VERSION ""

NS_ :

BS_:

BU_:

BO_ 3221225472 VECTOR__INDEPENDENT_SIG_MSG: 0 Vector__XXX
 SG_ NewSignal_0005 : 0|8@1+ (1,0) [0|0] "" Vector__XXX
 SG_ NewSignal_0006 : 8|8@1+ (1,0) [0|0] "" Vector__XXX
 SG_ STATE : 0|8@1+ (1,0) [0|0] "" Vector__XXX
 SG_ NODE_ID : 8|8@1+ (1,0) [1|127] "" Vector__XXX

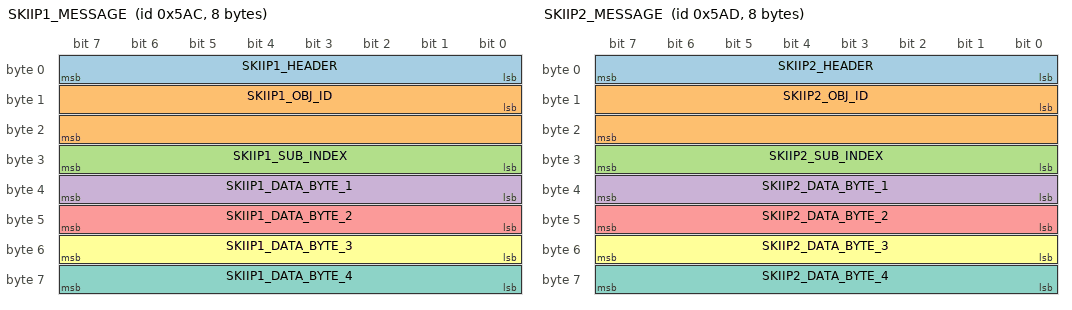
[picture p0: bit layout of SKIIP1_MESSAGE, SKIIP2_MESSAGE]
BO_ 1452 SKIIP1_MESSAGE: 8 Vector__XXX
 SG_ SKIIP1_HEADER : 0|8@1+ (1,0) [0|255] "" Vector__XXX
 SG_ SKIIP1_OBJ_ID : 8|16@1+ (1,0) [0|65535] "" Vector__XXX
 SG_ SKIIP1_SUB_INDEX : 24|8@1+ (1,0) [0|255] "" Vector__XXX
 SG_ SKIIP1_DATA_BYTE_1 : 32|8@1+ (1,0) [0|255] "" Vector__XXX
 SG_ SKIIP1_DATA_BYTE_2 : 40|8@1+ (1,0) [0|255] "" Vector__XXX
 SG_ SKIIP1_DATA_BYTE_3 : 48|8@1+ (1,0) [0|255] "" Vector__XXX
 SG_ SKIIP1_DATA_BYTE_4 : 56|8@1+ (1,0) [0|255] "" Vector__XXX

BO_ 1453 SKIIP2_MESSAGE: 8 Vector__XXX
 SG_ SKIIP2_HEADER : 0|8@1+ (1,0) [0|255] "" Vector__XXX
 SG_ SKIIP2_OBJ_ID : 8|16@1+ (1,0) [0|65535] "" Vector__XXX
 SG_ SKIIP2_SUB_INDEX : 24|8@1+ (1,0) [0|255] "" Vector__XXX
 SG_ SKIIP2_DATA_BYTE_1 : 32|8@1+ (1,0) [0|255] "" Vector__XXX
 SG_ SKIIP2_DATA_BYTE_2 : 40|8@1+ (1,0) [0|255] "" Vector__XXX
 SG_ SKIIP2_DATA_BYTE_3 : 48|8@1+ (1,0) [0|255] "" Vector__XXX
 SG_ SKIIP2_DATA_BYTE_4 : 56|8@1+ (1,0) [0|255] "" Vector__XXX

BO_ 1836 SKIIP1_MESSAGE_HEARTBEAT: 8 Vector__XXX
 SG_ SKIIP1_HEARTBEAT_STATE : 0|8@1+ (1,0) [4|127] "" Vector__XXX

BO_ 1837 SKIIP2_MESSAGE_HEARTBEAT: 8 Vector__XXX
 SG_ SKIIP2_HEARTBEAT_STATE : 0|8@1+ (1,0) [4|127] "" Vector__XXX

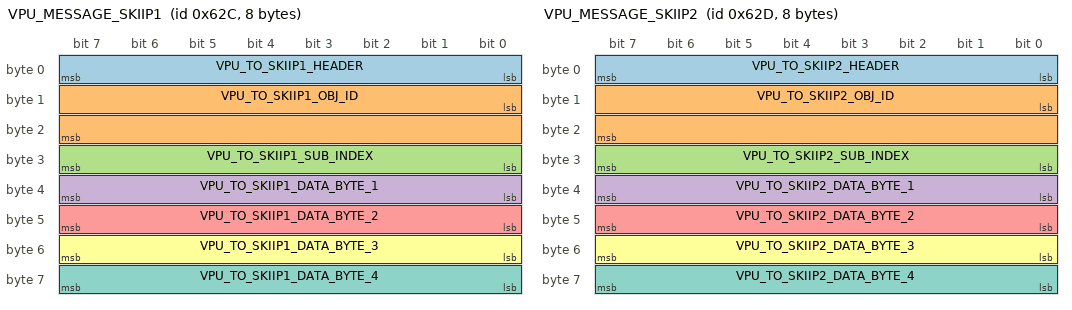
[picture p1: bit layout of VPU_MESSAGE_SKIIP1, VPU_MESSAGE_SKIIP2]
BO_ 1580 VPU_MESSAGE_SKIIP1: 8 Vector__XXX
 SG_ VPU_TO_SKIIP1_HEADER : 0|8@1+ (1,0) [0|255] "" Vector__XXX
 SG_ VPU_TO_SKIIP1_OBJ_ID : 8|16@1+ (1,0) [0|65535] "" Vector__XXX
 SG_ VPU_TO_SKIIP1_SUB_INDEX : 24|8@1+ (1,0) [0|255] "" Vector__XXX
 SG_ VPU_TO_SKIIP1_DATA_BYTE_1 : 32|8@1+ (1,0) [0|255] "" Vector__XXX
 SG_ VPU_TO_SKIIP1_DATA_BYTE_2 : 40|8@1+ (1,0) [0|255] "" Vector__XXX
 SG_ VPU_TO_SKIIP1_DATA_BYTE_3 : 48|8@1+ (1,0) [0|255] "" Vector__XXX
 SG_ VPU_TO_SKIIP1_DATA_BYTE_4 : 56|8@1+ (1,0) [0|255] "" Vector__XXX

BO_ 1581 VPU_MESSAGE_SKIIP2: 8 Vector__XXX
 SG_ VPU_TO_SKIIP2_HEADER : 0|8@1+ (1,0) [0|255] "" Vector__XXX
 SG_ VPU_TO_SKIIP2_OBJ_ID : 8|16@1+ (1,0) [0|65535] "" Vector__XXX
 SG_ VPU_TO_SKIIP2_SUB_INDEX : 24|8@1+ (1,0) [0|255] "" Vector__XXX
 SG_ VPU_TO_SKIIP2_DATA_BYTE_1 : 32|8@1+ (1,0) [0|255] "" Vector__XXX
 SG_ VPU_TO_SKIIP2_DATA_BYTE_2 : 40|8@1+ (1,0) [0|255] "" Vector__XXX
 SG_ VPU_TO_SKIIP2_DATA_BYTE_3 : 48|8@1+ (1,0) [0|255] "" Vector__XXX
 SG_ VPU_TO_SKIIP2_DATA_BYTE_4 : 56|8@1+ (1,0) [0|255] "" Vector__XXX

BO_ 0 CHANGE_CAN_OPEN_STATE: 8 Vector__XXX
 SG_ VPU_COMMAND_SKIIP : 0|8@1+ (1,0) [1|130] "" Vector__XXX
 SG_ NODE_ID_TO_CHANGE : 8|8@1+ (1,0) [1|127] "" Vector__XXX

VAL_ 1452 SKIIP1_HEADER 64 "READ_DEFAULT" ;
VAL_ 1452 SKIIP1_OBJ_ID 4096 "OBJ_NUMBER_DEVICE_TYPE" 4097 "OBJ_NUMBER_ERROR_REGISTER" 4104 "OBJ_NUMBER_MANUFACTURER_DEVICE_NAME" 4105 "OBJ_NUMBER_MANUFACTURER_HARDWARE_VERSION" 4106 "OBJ_NUMBER_MANUFACTURER_SOFTWARE_VERSION" 4112 "OBJ_NUMBER_STORE_PARAMTER_FIELD" 4119 "OBJ_NUMBER_PRODUCER_HEARTBEAT" 4120 "OBJ_NUMBER_IDENTITY_OBJECT" 4608 "OBJ_NUMBER_SERVER_SDO_PARAMTER_0" 12288 "OBJ_NUMBER_BAUD_RATE" 12289 "OBJ_NUMBER_OPERATION_TIME" 12290 "OBJ_NUMBER_DC_LINK_TRIP_LEVEL" 12291 "OBJ_NUMBER_TEMPERATURE_DCB" 12292 "OBJ_NUMBER_TEMPERATURE_PCB" 12293 "OBJ_NUMBER_SERIAL_PCB" 12294 "OBJ_NUMBER_SERIAL_SHUTTLE" 12295 "OBJ_NUMBER_ERROR_STATE" 12296 "OBJ_NUMBER_DC_LINK_DEACTIVATION" 12297 "OBJ_NUMBER_FRT_ACTIVATION" 12298 "OBJ_NUMBER_ERROR_RECORDER_LAST_VCE_ERROR" 12299 "OBJ_NUMBER_ERROR_RECORDER_ENTRY_1" 12300 "OBJ_NUMBER_ERROR_RECORDER_ENTRY_2" 12301 "OBJ_NUMBER_ERROR_RECORDER_ENTRY_3" 12302 "OBJ_NUMBER_ERROR_RECORDER_ENTRY_4" 12303 "OBJ_NUMBER_ERROR_RECORDER_ENTRY_5" 12304 "OBJ_NUMBER_ERROR_RECORDER_ENTRY_6" 12305 "OBJ_NUMBER_ERROR_RECORDER_ENTRY_7" 12306 "OBJ_NUMBER_ERROR_RECORDER_ENTRY_8" 12307 "OBJ_NUMBER_ERROR_RECORDER_ENTRY_9" 12308 "OBJ_NUMBER_ERROR_RECORDER_ENTRY_10" 12309 "OBJ_NUMBER_RESERVERD0" 12310 "OBJ_NUMBER_NODE_ID" 12311 "OBJ_NUMBER_PARALLEL_ENABLE" 16384 "OBJ_NUMBER_RESERVERD1" ;
VAL_ 1453 SKIIP2_HEADER 64 "READ_DEFAULT" ;
VAL_ 1453 SKIIP2_OBJ_ID 4096 "OBJ_NUMBER_DEVICE_TYPE" 4097 "OBJ_NUMBER_ERROR_REGISTER" 4104 "OBJ_NUMBER_MANUFACTURER_DEVICE_NAME" 4105 "OBJ_NUMBER_MANUFACTURER_HARDWARE_VERSION" 4106 "OBJ_NUMBER_MANUFACTURER_SOFTWARE_VERSION" 4112 "OBJ_NUMBER_STORE_PARAMTER_FIELD" 4119 "OBJ_NUMBER_PRODUCER_HEARTBEAT" 4120 "OBJ_NUMBER_IDENTITY_OBJECT" 4608 "OBJ_NUMBER_SERVER_SDO_PARAMTER_0" 12288 "OBJ_NUMBER_BAUD_RATE" 12289 "OBJ_NUMBER_OPERATION_TIME" 12290 "OBJ_NUMBER_DC_LINK_TRIP_LEVEL" 12291 "OBJ_NUMBER_TEMPERATURE_DCB" 12292 "OBJ_NUMBER_TEMPERATURE_PCB" 12293 "OBJ_NUMBER_SERIAL_PCB" 12294 "OBJ_NUMBER_SERIAL_SHUTTLE" 12295 "OBJ_NUMBER_ERROR_STATE" 12296 "OBJ_NUMBER_DC_LINK_DEACTIVATION" 12297 "OBJ_NUMBER_FRT_ACTIVATION" 12298 "OBJ_NUMBER_ERROR_RECORDER_LAST_VCE_ERROR" 12299 "OBJ_NUMBER_ERROR_RECORDER_ENTRY_1" 12300 "OBJ_NUMBER_ERROR_RECORDER_ENTRY_2" 12301 "OBJ_NUMBER_ERROR_RECORDER_ENTRY_3" 12302 "OBJ_NUMBER_ERROR_RECORDER_ENTRY_4" 12303 "OBJ_NUMBER_ERROR_RECORDER_ENTRY_5" 12304 "OBJ_NUMBER_ERROR_RECORDER_ENTRY_6" 12305 "OBJ_NUMBER_ERROR_RECORDER_ENTRY_7" 12306 "OBJ_NUMBER_ERROR_RECORDER_ENTRY_8" 12307 "OBJ_NUMBER_ERROR_RECORDER_ENTRY_9" 12308 "OBJ_NUMBER_ERROR_RECORDER_ENTRY_10" 12309 "OBJ_NUMBER_RESERVERD0" 12310 "OBJ_NUMBER_NODE_ID" 12311 "OBJ_NUMBER_PARALLEL_ENABLE" 16384 "OBJ_NUMBER_RESERVERD1" ;
VAL_ 1836 SKIIP1_HEARTBEAT_STATE 4 "STOPPED_STATE" 5 "PRE_OPERATIONAL_STATE" 127 "OPERATIONAL_STATE" ;
VAL_ 1837 SKIIP2_HEARTBEAT_STATE 4 "STOPPED_STATE" 5 "PRE_OPERATIONAL_STATE" 127 "OPERATIONAL_STATE" ;
VAL_ 1580 VPU_TO_SKIIP1_HEADER 64 "READ_DEFAULT" ;
VAL_ 1580 VPU_TO_SKIIP1_OBJ_ID 4096 "OBJ_NUMBER_DEVICE_TYPE" 4097 "OBJ_NUMBER_ERROR_REGISTER" 4104 "OBJ_NUMBER_MANUFACTURER_DEVICE_NAME" 4105 "OBJ_NUMBER_MANUFACTURER_HARDWARE_VERSION" 4106 "OBJ_NUMBER_MANUFACTURER_SOFTWARE_VERSION" 4112 "OBJ_NUMBER_STORE_PARAMTER_FIELD" 4119 "OBJ_NUMBER_PRODUCER_HEARTBEAT" 4120 "OBJ_NUMBER_IDENTITY_OBJECT" 4608 "OBJ_NUMBER_SERVER_SDO_PARAMTER_0" 12288 "OBJ_NUMBER_BAUD_RATE" 12289 "OBJ_NUMBER_OPERATION_TIME" 12290 "OBJ_NUMBER_DC_LINK_TRIP_LEVEL" 12291 "OBJ_NUMBER_TEMPERATURE_DCB" 12292 "OBJ_NUMBER_TEMPERATURE_PCB" 12293 "OBJ_NUMBER_SERIAL_PCB" 12294 "OBJ_NUMBER_SERIAL_SHUTTLE" 12295 "OBJ_NUMBER_ERROR_STATE" 12296 "OBJ_NUMBER_DC_LINK_DEACTIVATION" 12297 "OBJ_NUMBER_FRT_ACTIVATION" 12298 "OBJ_NUMBER_ERROR_RECORDER_LAST_VCE_ERROR" 12299 "OBJ_NUMBER_ERROR_RECORDER_ENTRY_1" 12300 "OBJ_NUMBER_ERROR_RECORDER_ENTRY_2" 12301 "OBJ_NUMBER_ERROR_RECORDER_ENTRY_3" 12302 "OBJ_NUMBER_ERROR_RECORDER_ENTRY_4" 12303 "OBJ_NUMBER_ERROR_RECORDER_ENTRY_5" 12304 "OBJ_NUMBER_ERROR_RECORDER_ENTRY_6" 12305 "OBJ_NUMBER_ERROR_RECORDER_ENTRY_7" 12306 "OBJ_NUMBER_ERROR_RECORDER_ENTRY_8" 12307 "OBJ_NUMBER_ERROR_RECORDER_ENTRY_9" 12308 "OBJ_NUMBER_ERROR_RECORDER_ENTRY_10" 12309 "OBJ_NUMBER_RESERVERD0" 12310 "OBJ_NUMBER_NODE_ID" 12311 "OBJ_NUMBER_PARALLEL_ENABLE" 16384 "OBJ_NUMBER_RESERVERD1" ;
VAL_ 1581 VPU_TO_SKIIP2_HEADER 64 "READ_DEFAULT" ;
VAL_ 1581 VPU_TO_SKIIP2_OBJ_ID 4096 "OBJ_NUMBER_DEVICE_TYPE" 4097 "OBJ_NUMBER_ERROR_REGISTER" 4104 "OBJ_NUMBER_MANUFACTURER_DEVICE_NAME" 4105 "OBJ_NUMBER_MANUFACTURER_HARDWARE_VERSION" 4106 "OBJ_NUMBER_MANUFACTURER_SOFTWARE_VERSION" 4112 "OBJ_NUMBER_STORE_PARAMTER_FIELD" 4119 "OBJ_NUMBER_PRODUCER_HEARTBEAT" 4120 "OBJ_NUMBER_IDENTITY_OBJECT" 4608 "OBJ_NUMBER_SERVER_SDO_PARAMTER_0" 12288 "OBJ_NUMBER_BAUD_RATE" 12289 "OBJ_NUMBER_OPERATION_TIME" 12290 "OBJ_NUMBER_DC_LINK_TRIP_LEVEL" 12291 "OBJ_NUMBER_TEMPERATURE_DCB" 12292 "OBJ_NUMBER_TEMPERATURE_PCB" 12293 "OBJ_NUMBER_SERIAL_PCB" 12294 "OBJ_NUMBER_SERIAL_SHUTTLE" 12295 "OBJ_NUMBER_ERROR_STATE" 12296 "OBJ_NUMBER_DC_LINK_DEACTIVATION" 12297 "OBJ_NUMBER_FRT_ACTIVATION" 12298 "OBJ_NUMBER_ERROR_RECORDER_LAST_VCE_ERROR" 12299 "OBJ_NUMBER_ERROR_RECORDER_ENTRY_1" 12300 "OBJ_NUMBER_ERROR_RECORDER_ENTRY_2" 12301 "OBJ_NUMBER_ERROR_RECORDER_ENTRY_3" 12302 "OBJ_NUMBER_ERROR_RECORDER_ENTRY_4" 12303 "OBJ_NUMBER_ERROR_RECORDER_ENTRY_5" 12304 "OBJ_NUMBER_ERROR_RECORDER_ENTRY_6" 12305 "OBJ_NUMBER_ERROR_RECORDER_ENTRY_7" 12306 "OBJ_NUMBER_ERROR_RECORDER_ENTRY_8" 12307 "OBJ_NUMBER_ERROR_RECORDER_ENTRY_9" 12308 "OBJ_NUMBER_ERROR_RECORDER_ENTRY_10" 12309 "OBJ_NUMBER_RESERVERD0" 12310 "OBJ_NUMBER_NODE_ID" 12311 "OBJ_NUMBER_PARALLEL_ENABLE" 16384 "OBJ_NUMBER_RESERVERD1" ;
VAL_ 0 VPU_COMMAND_SKIIP 1 "OPERATIONAL_STATE" 2 "STOP_STATE" 128 "PRE_OPERATIONAL_STATE" 129 "RESET_NODE" 130 "RESET_COMMUNICATION" ;
